# ATmega64C1 register map
Vendor: Atmel; File version: 1.0
CPU: other r0p0, little endian, no MPU, no FPU, 4 interrupt priority bits
Registers are 8-bit, read-write, reset 0x0 unless marked. A register's access mark holds for its fields unless they carry their own. Offsets are from the block's base; [hi:lo] are bit positions; {n}, {i} and the like mark numbered series.

## ADC — Analog-to-Digital Converter
Base 0x00800075
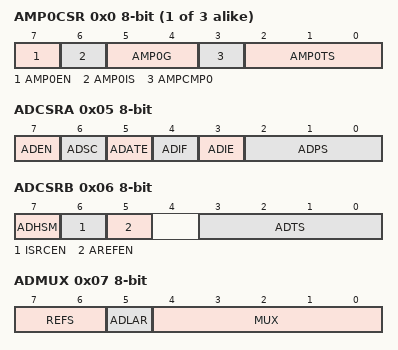
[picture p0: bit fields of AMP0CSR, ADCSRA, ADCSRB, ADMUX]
{0x0+i} AMP{i}CSR (i=0..2)
  [7] AMP{i}EN
  [6] AMP{i}IS
  [5:4] AMP{i}G
  [3] AMPCMP{i} — Amplifier {i} - Comparator {i} Connection
  [2:0] AMP{i}TS
0x03 ADC 16-bit (reset mask 0xFF) — ADC Data Register Bytes
0x05 ADCSRA — The ADC Control and Status register (read-only for debugger)
  [7] ADEN — ADC Enable
  [6] ADSC — ADC Start Conversion
  [5] ADATE — ADC Auto Trigger Enable
  [4] ADIF — ADC Interrupt Flag
  [3] ADIE — ADC Interrupt Enable
  [2:0] ADPS — ADC Prescaler Select Bits
0x06 ADCSRB — ADC Control and Status Register B
  [7] ADHSM — ADC High Speed Mode
  [6] ISRCEN — Current Source Enable
  [5] AREFEN — Analog Reference pin Enable
  [3:0] ADTS — ADC Auto Trigger Sources
    0=FREE_RUNNING_MODE; 1=ANALOG_COMPARATOR; 2=EXTERNAL_INTERRUPT_REQUEST_0; 3=TIMER_COUNTER0_COMPARE_MATCH_A; 4=TIMER_COUNTER0_OVERFLOW; 5=TIMER_COUNTER1_COMPARE_MATCH_B; 6=TIMER_COUNTER1_OVERFLOW; 7=TIMER_COUNTER1_CAPTURE_EVENT; 8=PSC0ASY_EVENT; 9=PSC1ASY_EVENT; 10=PSC2ASY_EVENT; 11=ANALOG_COMPARATOR_1; 12=ANALOG_COMPARATOR_2
0x07 ADMUX — The ADC multiplexer Selection Register
  [7:6] REFS — Reference Selection Bits
    0=AREF_INTERNAL_VREF_TURNED_OFF; 1=AVCC_REFERENCE; 3=INTERNAL_2_56V_VOLTAGE_REFERENCE
  [5] ADLAR — Left Adjust Result
  [4:0] MUX — Analog Channel and Gain Selection Bits
    {v}=ADC{v} (ADC input pin {v}) (v=0..10); 11=TEMPSENSE (Temperature sensor); 12=VCC4 (Internal VCC / 4); 13=ISRC (Current source); 14=AMP0 (Analog Differential Amplifier 0); 15=AMP1 (Analog Differential Amplifier 1); 16=AMP2 (Analog Differential Amplifier 2); 17=BNDGAP (Bandgap); 18=GND (0V (GND))
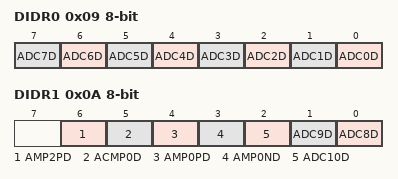
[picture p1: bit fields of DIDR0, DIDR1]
0x09 DIDR0 — Digital Input Disable Register 0
  [n] ADC{n}D (n=0..7) — ADC{n} Digital input Disable
0x0A DIDR1 — Digital Input Disable Register 0
  [6] AMP2PD — AMP2P Pin Digital input Disable
  [5] ACMP0D — ACMP0 Pin Digital input Disable
  [4] AMP0PD — AMP0P Pin Digital input Disable
  [3] AMP0ND — AMP0N Pin Digital input Disable
  [2] ADC10D — ADC10 Pin Digital input Disable
  [1] ADC9D — ADC9 Pin Digital input Disable
  [0] ADC8D — ADC8 Pin Digital input Disable

## CPU — CPU Registers
Base 0x00800039
0x00 GPIOR1 — General Purpose IO Register 1
  [7:0] GPIOR — General Purpose IO Register 1 bis
0x01 GPIOR2 — General Purpose IO Register 2
  [7:0] GPIOR — General Purpose IO Register 2 bis
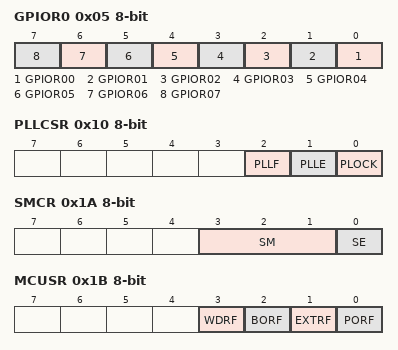
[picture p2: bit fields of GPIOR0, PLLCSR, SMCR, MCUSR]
0x05 GPIOR0 — General Purpose IO Register 0
  [n] GPIOR{n:02} (n=0..7) — General Purpose IO Register 0 bit {n}
0x10 PLLCSR — PLL Control And Status Register
  [2] PLLF — PLL Factor
  [1] PLLE — PLL Enable
  [0] PLOCK — PLL Lock Detector
0x1A SMCR — Sleep Mode Control Register
  [3:1] SM — Sleep Mode Select bits
    0=IDLE; 1=ADC (ADC Noise Reduction (If Available)); 2=PDOWN (Power Down); 6=STDBY (Standby)
  [0] SE — Sleep Enable
0x1B MCUSR — MCU Status Register
  [3] WDRF — Watchdog Reset Flag
  [2] BORF — Brown-out Reset Flag
  [1] EXTRF — External Reset Flag
  [0] PORF — Power-on reset flag
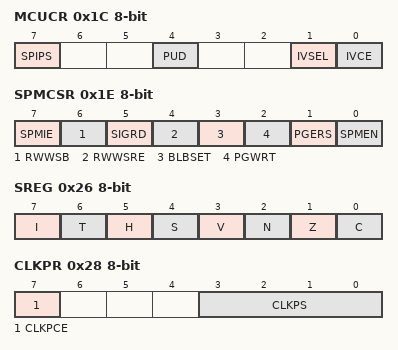
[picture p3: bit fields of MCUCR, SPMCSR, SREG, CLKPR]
0x1C MCUCR — MCU Control Register
  [7] SPIPS — SPI Pin Select
  [4] PUD — Pull-up disable
  [1] IVSEL — Interrupt Vector Select
  [0] IVCE — Interrupt Vector Change Enable
0x1E SPMCSR — Store Program Memory Control Register
  [7] SPMIE — SPM Interrupt Enable
  [6] RWWSB — Read While Write Section Busy
  [5] SIGRD — Signature Row Read
  [4] RWWSRE — Read While Write section read enable
  [3] BLBSET — Boot Lock Bit Set
  [2] PGWRT — Page Write
  [1] PGERS — Page Erase
  [0] SPMEN — Store Program Memory Enable
0x24 SP 16-bit (reset mask 0xFF) — Stack Pointer
0x26 SREG — Status Register
  [7] I — Global Interrupt Enable
  [6] T — Bit Copy Storage
  [5] H — Half Carry Flag
  [4] S — Sign Bit
  [3] V — Two's Complement Overflow Flag
  [2] N — Negative Flag
  [1] Z — Zero Flag
  [0] C — Carry Flag
0x28 CLKPR
  [7] CLKPCE
  [3:0] CLKPS
    0=1; 1=2; 2=4; 3=8; 4=16; 5=32; 6=64; 7=128; 8=256
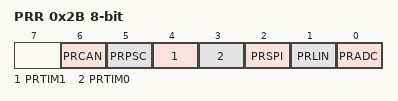
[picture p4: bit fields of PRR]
0x2B PRR — Power Reduction Register
  [6] PRCAN — Power Reduction CAN
  [5] PRPSC — Power Reduction PSC
  [4] PRTIM1 — Power Reduction Timer/Counter1
  [3] PRTIM0 — Power Reduction Timer/Counter0
  [2] PRSPI — Power Reduction Serial Peripheral Interface
  [1] PRLIN — Power Reduction LIN UART
  [0] PRADC — Power Reduction ADC
0x2D OSCCAL — Oscillator Calibration Value (read-only for debugger)
  [7:0] OSCCAL — Oscillator Calibration
